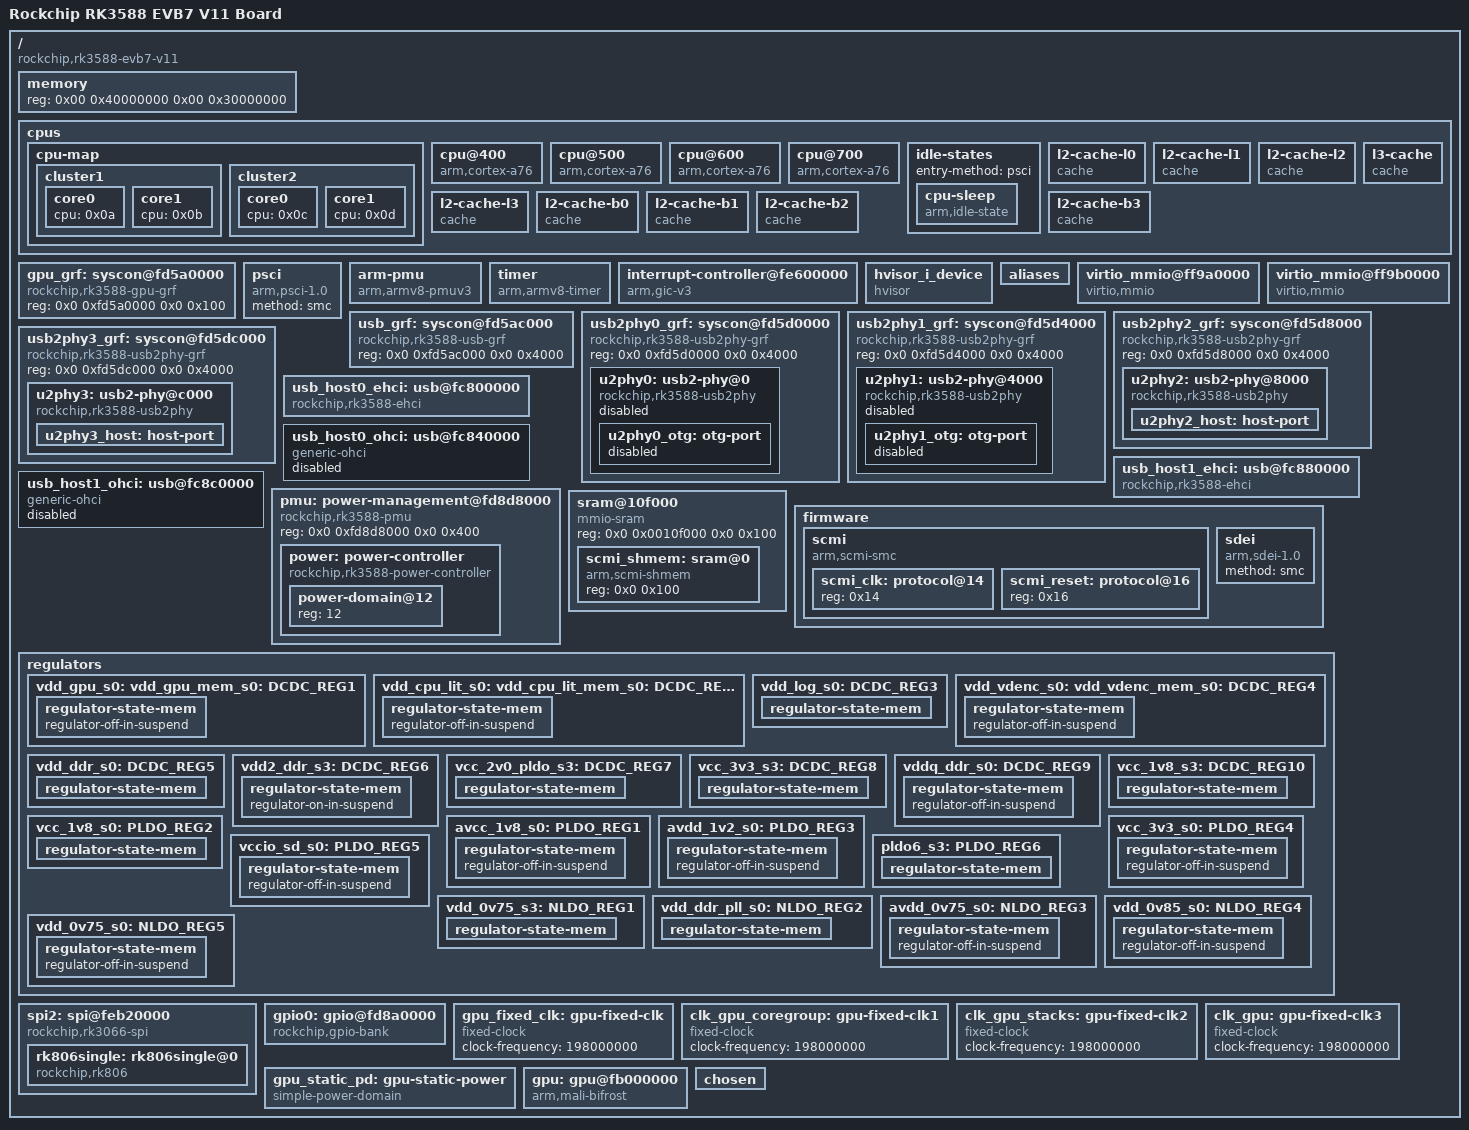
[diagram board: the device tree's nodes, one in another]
/dts-v1/;

/memreserve/	0x0000000008300000 0x0000000000047000;
/ {
	serial-number = "fe9d722c1f58159b";
	compatible = "rockchip,rk3588-evb7-v11\0rockchip,rk3588";
	interrupt-parent = <0x01>;
	#address-cells = <0x02>;
	#size-cells = <0x02>;
	model = "Rockchip RK3588 EVB7 V11 Board";

	memory {
		reg = <0x00 0x40000000 0x00 0x30000000>;
		device_type = "memory";
	};

	/*cpus 
		#address-cells = <0x01>;
		#size-cells = <0x00>;

		cpu-map {
			cluster0 {
				core2 {
					cpu = <0x08>;
				};

				core3 {
					cpu = <0x09>;
				};


			};
		};

		cpu@200 {
			device_type = "cpu";
			compatible = "arm,cortex-a55";
			reg = <0x200>;
			enable-method = "psci";
			capacity-dmips-mhz = <0x212>;
			clocks = <0x0e 0x00>;
			cpu-idle-states = <0x10>;
			i-cache-size = <0x8000>;
			i-cache-line-size = <0x40>;
			i-cache-sets = <0x80>;
			d-cache-size = <0x8000>;
			d-cache-line-size = <0x40>;
			d-cache-sets = <0x80>;
			next-level-cache = <0x14>;
			phandle = <0x08>;
		};


		cpu@300 {
			device_type = "cpu";
			compatible = "arm,cortex-a55";
			reg = <0x300>;
			enable-method = "psci";
			capacity-dmips-mhz = <0x212>;
			clocks = <0x0e 0x00>;
			cpu-idle-states = <0x10>;
			i-cache-size = <0x8000>;
			i-cache-line-size = <0x40>;
			i-cache-sets = <0x80>;
			d-cache-size = <0x8000>;
			d-cache-line-size = <0x40>;
			d-cache-sets = <0x80>;
			next-level-cache = <0x15>;
			phandle = <0x09>;
		};

*/
cpus {
		#address-cells = <0x01>;
		#size-cells = <0x00>;

		cpu-map {


			cluster1 {

				core0 {
					cpu = <0x0a>;
				};

				core1 {
					cpu = <0x0b>;
				};
			};


			cluster2 {

				core0 {
					cpu = <0x0c>;
				};

				core1 {
					cpu = <0x0d>;
				};
			};
		};

		cpu@400 {
			device_type = "cpu";
			compatible = "arm,cortex-a76";
			reg = <0x400>;
			enable-method = "psci";
			capacity-dmips-mhz = <0x400>;
			clocks = <0x0e 0x02>;
			operating-points-v2 = <0x0f>;
			cpu-idle-states = <0x10>;
			i-cache-size = <0x10000>;
			i-cache-line-size = <0x40>;
			i-cache-sets = <0x100>;
			d-cache-size = <0x10000>;
			d-cache-line-size = <0x40>;
			d-cache-sets = <0x100>;
			next-level-cache = <0x11>;
			#cooling-cells = <0x02>;
			dynamic-power-coefficient = <0x12c>;
			cpu-supply = <0x12>;
			mem-supply = <0x12>;
			phandle = <0x0a>;
		};

		cpu@500 {
			device_type = "cpu";
			compatible = "arm,cortex-a76";
			reg = <0x500>;
			enable-method = "psci";
			capacity-dmips-mhz = <0x400>;
			clocks = <0x0e 0x02>;
			operating-points-v2 = <0x0f>;
			cpu-idle-states = <0x10>;
			i-cache-size = <0x10000>;
			i-cache-line-size = <0x40>;
			i-cache-sets = <0x100>;
			d-cache-size = <0x10000>;
			d-cache-line-size = <0x40>;
			d-cache-sets = <0x100>;
			next-level-cache = <0x13>;
			phandle = <0x0b>;
		};


		cpu@600 {
			device_type = "cpu";
			compatible = "arm,cortex-a76";
			reg = <0x600>;
			enable-method = "psci";
			capacity-dmips-mhz = <0x400>;
			clocks = <0x0e 0x03>;
			operating-points-v2 = <0x14>;
			cpu-idle-states = <0x10>;
			i-cache-size = <0x10000>;
			i-cache-line-size = <0x40>;
			i-cache-sets = <0x100>;
			d-cache-size = <0x10000>;
			d-cache-line-size = <0x40>;
			d-cache-sets = <0x100>;
			next-level-cache = <0x15>;
			#cooling-cells = <0x02>;
			dynamic-power-coefficient = <0x12c>;
			cpu-supply = <0x16>;
			mem-supply = <0x16>;
			phandle = <0x0c>;
		};

		cpu@700 {
			device_type = "cpu";
			compatible = "arm,cortex-a76";
			reg = <0x700>;
			enable-method = "psci";
			capacity-dmips-mhz = <0x400>;
			clocks = <0x0e 0x03>;
			operating-points-v2 = <0x14>;
			cpu-idle-states = <0x10>;
			i-cache-size = <0x10000>;
			i-cache-line-size = <0x40>;
			i-cache-sets = <0x100>;
			d-cache-size = <0x10000>;
			d-cache-line-size = <0x40>;
			d-cache-sets = <0x100>;
			next-level-cache = <0x17>;
			phandle = <0x0d>;
		};

		idle-states {
			entry-method = "psci";
			cpu-sleep {
				compatible = "arm,idle-state";
				local-timer-stop;
				arm,psci-suspend-param = <0x10000>;
				entry-latency-us = <0x64>;
				exit-latency-us = <0x78>;
				min-residency-us = <0x3e8>;
				phandle = <0x10>;
			};
		};

		l2-cache-l0 {
			compatible = "cache";
			cache-size = <0x20000>;
			cache-line-size = <0x40>;
			cache-sets = <0x200>;
			next-level-cache = <0x1e>;
			phandle = <0x11>;
		};

		l2-cache-l1 {
			compatible = "cache";
			cache-size = <0x20000>;
			cache-line-size = <0x40>;
			cache-sets = <0x200>;
			next-level-cache = <0x1e>;
			phandle = <0x13>;
		};

		l2-cache-l2 {
			compatible = "cache";
			cache-size = <0x20000>;
			cache-line-size = <0x40>;
			cache-sets = <0x200>;
			next-level-cache = <0x1e>;
			phandle = <0x14>;
		};

		l2-cache-l3 {
			compatible = "cache";
			cache-size = <0x20000>;
			cache-line-size = <0x40>;
			cache-sets = <0x200>;
			next-level-cache = <0x1e>;
			phandle = <0x15>;
		};

		l2-cache-b0 {
			compatible = "cache";
			cache-size = <0x80000>;
			cache-line-size = <0x40>;
			cache-sets = <0x400>;
			next-level-cache = <0x1e>;
			phandle = <0x17>;
		};

		l2-cache-b1 {
			compatible = "cache";
			cache-size = <0x80000>;
			cache-line-size = <0x40>;
			cache-sets = <0x400>;
			next-level-cache = <0x1e>;
			phandle = <0x19>;
		};

		l2-cache-b2 {
			compatible = "cache";
			cache-size = <0x80000>;
			cache-line-size = <0x40>;
			cache-sets = <0x400>;
			next-level-cache = <0x1e>;
			phandle = <0x1b>;
		};

		l2-cache-b3 {
			compatible = "cache";
			cache-size = <0x80000>;
			cache-line-size = <0x40>;
			cache-sets = <0x400>;
			next-level-cache = <0x1e>;
			phandle = <0x1d>;
		};

		l3-cache {
			compatible = "cache";
			cache-size = <0x300000>;
			cache-line-size = <0x40>;
			cache-sets = <0x1000>;
			phandle = <0x1e>;
		};
	};

gpu_grf: syscon@fd5a0000 {
  compatible = "rockchip,rk3588-gpu-grf", "syscon";
  reg = <0x0 0xfd5a0000 0x0 0x100>;
 };

/*
php_grf: syscon@fd5b0000 {
  compatible = "rockchip,rk3588-php-grf", "syscon";
  reg = <0x0 0xfd5b0000 0x0 0x1000>;
 };

cru: clock-controller@fd7c0000 {
	     compatible = "rockchip,rk3588-cru";
	     rockchip,grf = <&php_grf>;
	     reg = <0x0 0xfd7c0000 0x0 0x5c000>;
#clock-cells = <1>;
#reset-cells = <1>;

	     assigned-clocks =
		     <&cru 9>, <&cru 5>,
		     <&cru 8>, <&cru 7>,
		     <&cru 216>,
		     <&cru 218>, <&cru 217>,
		     <&cru 270>, <&cru 271>,
		     <&cru 272>, <&cru 665>,
		     <&cru 666>,
		     <&cru 123>, <&cru 236>,
		     <&cru 276>, <&cru 520>,
		     <&cru 526>, <&cru 543>,
		     <&cru 119>;
	     assigned-clock-rates =
		     <1100000000>, <786432000>,
		     <850000000>, <1188000000>,
		     <702000000>,
		     <400000000>, <500000000>,
		     <750000000>, <100000000>,
		     <400000000>, <100000000>,
		     <200000000>,
		     <375000000>, <150000000>,
		     <200000000>, <12000000>,
		     <12000000>, <99000000>,
		     <20000000>;
     };


*/


	psci {
		compatible = "arm,psci-1.0";
		method = "smc";
	};

	arm-pmu {
		compatible = "arm,armv8-pmuv3";
		interrupts = <0x01 0x07 0x08>;
		interrupt-affinity = <0x06 0x07 0x08 0x09 0x0a 0x0b 0x0c 0x0d>;
		phandle = <0x220>;
	};

	timer {
		compatible = "arm,armv8-timer";
		interrupts = <0x01 0x0d 0xf04 0x01 0x0e 0xf04 0x01 0x0b 0xf04 0x01 0x0a 0xf04>;
	};

	interrupt-controller@fe600000 {
		compatible = "arm,gic-v3";
		#interrupt-cells = <0x03>;
		#address-cells = <0x02>;
		#size-cells = <0x02>;
		ranges;
		interrupt-controller;
		reg = <0x00 0xfe600000 0x00 0x10000 0x00 0xfe680000 0x00 0x100000>;
		interrupts = <0x01 0x09 0x04>;
		phandle = <0x01>;
	};
	hvisor_i_device {
                                compatible = "hvisor";
                                interrupt-parent = <0x01>;
                                interrupts = <0x00 0x22 0x01>;
                        };


	
    aliases {
	};

	// virtio blk
	virtio_mmio@ff9a0000 {
		dma-coherent;
		interrupt-parent = <0x01>;
		interrupts = <0x0 0x2e 0x1>;
		reg = <0x0 0xff9a0000 0x0 0x200>;
		compatible = "virtio,mmio";
	};

	// virtio serial
	virtio_mmio@ff9b0000 {
		dma-coherent;
		interrupt-parent = <0x01>;
		interrupts = <0x0 0x2c 0x1>;
		reg = <0x0 0xff9b0000 0x0 0x200>;
		compatible = "virtio,mmio";
	};


	// serial@feb50000 {
	// 	compatible = "rockchip,rk3588-uart\0snps,dw-apb-uart";
	// 	reg = <0x00 0xfeb50000 0x00 0x100>;
	// 	interrupts = <0x00 0x14d 0x04>;
	// 	//clocks = <0x02 0xbb 0x02 0xac>;
	// 	//clock-names = "baudclk\0apb_pclk";
	// 	reg-shift = <0x02>;
	// 	reg-io-width = <0x04>;
	// 	//pinctrl-names = "default";
	// 	//pinctrl-0 = <0x16d>;
	// 	status = "okay";
	// 	phandle = <0x2e2>;
	// };

/*
 php_grf: syscon@fd5b0000 {
  compatible = "rockchip,rk3588-php-grf", "syscon";
  reg = <0x0 0xfd5b0000 0x0 0x1000>;
 };


cru: clock-controller@fd7c0000 {
  compatible = "rockchip,rk3588-cru";
  rockchip,grf = <&php_grf>;
  reg = <0x0 0xfd7c0000 0x0 0x5c000>;
  #clock-cells = <1>;
  #reset-cells = <1>;

 };
*/


usb_grf: syscon@fd5ac000 {
  compatible = "rockchip,rk3588-usb-grf", "syscon";
  reg = <0x0 0xfd5ac000 0x0 0x4000>;
 };

usb2phy0_grf: syscon@fd5d0000 {
  compatible = "rockchip,rk3588-usb2phy-grf", "syscon",
        "simple-mfd";
  reg = <0x0 0xfd5d0000 0x0 0x4000>;
  #address-cells = <1>;
  #size-cells = <1>;

  u2phy0: usb2-phy@0 {
   compatible = "rockchip,rk3588-usb2phy";
   reg = <0x0 0x10>;
   interrupts = <0 393 4>;
  // resets = <&cru 786503>, <&cru 1160>;
 // reset-names = "phy", "apb";
   clock-output-names = "usb480m_phy0";
   #clock-cells = <0>;
   rockchip,usbctrl-grf = <&usb_grf>;
   status = "disable";

   u2phy0_otg: otg-port {
    #phy-cells = <0>;
    status = "disabled";
   };
  };
 };

 usb2phy1_grf: syscon@fd5d4000 {
  compatible = "rockchip,rk3588-usb2phy-grf", "syscon",
        "simple-mfd";
  reg = <0x0 0xfd5d4000 0x0 0x4000>;
  #address-cells = <1>;
  #size-cells = <1>;

  u2phy1: usb2-phy@4000 {
   compatible = "rockchip,rk3588-usb2phy";
   reg = <0x4000 0x10>;
   interrupts = <0 394 4>;
   //resets = <&cru 786504>, <&cru 1161>;
   //reset-names = "phy", "apb";
   //clocks = <&cru 693>;
   //clock-names = "phyclk";
   clock-output-names = "usb480m_phy1";
   #clock-cells = <0>;
   rockchip,usbctrl-grf = <&usb_grf>;
   status = "disable";

   u2phy1_otg: otg-port {
    #phy-cells = <0>;
    status = "disabled";
   };
  };
 };

usb2phy2_grf: syscon@fd5d8000 {
  compatible = "rockchip,rk3588-usb2phy-grf", "syscon",
        "simple-mfd";
  reg = <0x0 0xfd5d8000 0x0 0x4000>;
  #address-cells = <1>;
  #size-cells = <1>;

  u2phy2: usb2-phy@8000 {
   compatible = "rockchip,rk3588-usb2phy";
   reg = <0x8000 0x10>;
   interrupts = <0 391 4>;
   //resets = <&cru 786505>, <&cru 1162>;
   //reset-names = "phy", "apb";
   //clocks = <&cru 693>;
   //clock-names = "phyclk";
   clock-output-names = "usb480m_phy2";
   #clock-cells = <0>;
   status = "okay";

   u2phy2_host: host-port {
    #phy-cells = <0>;
    status = "okay";
   };
  };
 };


usb2phy3_grf: syscon@fd5dc000 {
  compatible = "rockchip,rk3588-usb2phy-grf", "syscon",
        "simple-mfd";
  reg = <0x0 0xfd5dc000 0x0 0x4000>;
  #address-cells = <1>;
  #size-cells = <1>;

  u2phy3: usb2-phy@c000 {
   compatible = "rockchip,rk3588-usb2phy";
   reg = <0xc000 0x10>;
   interrupts = <0 392 4>;
  // resets = <&cru 786506>, <&cru 1163>;
   //reset-names = "phy", "apb";
   //clocks = <&cru 693>;
   clock-names = "phyclk";
   clock-output-names = "usb480m_phy3";
   #clock-cells = <0>;
   status = "okay";

   u2phy3_host: host-port {
    #phy-cells = <0>;
    status = "okay";
   };
  };
 };
/*&u2phy0 {
 status = "okay";
};

*/
/*
&u2phy1 {
 status = "okay";
};

&u2phy2 {
 status = "okay";
};

&u2phy3 {
 status = "disable";
};



&u2phy2_host {
 //phy-supply = <&vcc5v0_host>;
 status = "okay";
};

&u2phy3_host {
 //phy-supply = <&vcc5v0_host>;
 status = "okay";
};
*/



usb_host0_ehci: usb@fc800000 {
  compatible = "rockchip,rk3588-ehci", "generic-ehci";
  reg = <0x0 0xfc800000 0x0 0x40000>;
  interrupts = <0 215 4>;
  //clocks = <&cru 413>, <&cru 414>, <&u2phy2>;
  //clock-names = "usbhost", "arbiter", "utmi";
  companion = <&usb_host0_ohci>;
  phys = <&u2phy2_host>;
  phy-names = "usb2-phy";
 // power-domains = <&power 31>;
  status = "okay";
 };

 usb_host0_ohci: usb@fc840000 {
  compatible = "generic-ohci";
  reg = <0x0 0xfc840000 0x0 0x40000>;
  interrupts = <0 216 4>;
  //clocks = <&cru 413>, <&cru 414>, <&u2phy2>;
  //clock-names = "usbhost", "arbiter", "utmi";
  phys = <&u2phy2_host>;
  phy-names = "usb2-phy";
  //power-domains = <&power 31>;
  status = "disable";
 };

/*
&usb_host0_ehci {
 status = "okay";
};

&usb_host0_ohci {
 status = "okay";
};
*/

usb_host1_ehci: usb@fc880000 {
  compatible = "rockchip,rk3588-ehci", "generic-ehci";
  reg = <0x0 0xfc880000 0x0 0x40000>;
  interrupts = <0 218 4>;
  //clocks = <&cru 415>, <&cru 416>, <&u2phy3>;
  //clock-names = "usbhost", "arbiter", "utmi";
  companion = <&usb_host1_ohci>;
  phys = <&u2phy3_host>;
  phy-names = "usb2-phy";
  //power-domains = <&power 31>;
  status = "okay";
 };

 usb_host1_ohci: usb@fc8c0000 {
  compatible = "generic-ohci";
  reg = <0x0 0xfc8c0000 0x0 0x40000>;
  interrupts = <0 219 4>;
  //clocks = <&cru 415>, <&cru 416>, <&u2phy3>;
  //clock-names = "usbhost", "arbiter", "utmi";
  phys = <&u2phy3_host>;
  phy-names = "usb2-phy";
  //power-domains = <&power 31>;
  status = "disable";
 };

/*
&usb_host1_ehci {
 status = "okay";
};

&usb_host1_ohci {
 status = "okay";
};
*/
/*
usbdrd3_1: usbdrd3_1 {
  compatible = "rockchip,rk3588-dwc3", "rockchip,rk3399-dwc3";
  //clocks = <&cru 422>, <&cru 421>,
   // <&cru 420>;
  //clock-names = "ref", "suspend", "bus";
  #address-cells = <2>;
  #size-cells = <2>;
  ranges;
  status = "okay";

  usbdrd_dwc3_1: usb@fc400000 {
   compatible = "snps,dwc3";
   reg = <0x0 0xfc400000 0x0 0x400000>;
   interrupts = <0 221 4>;
   //power-domains = <&power 31>;
   //resets = <&cru 679>;
   //reset-names = "usb3-otg";
   dr_mode = "host";
   phys = <&usbdp_phy1_u3>;
   phy-names = "usb3-phy";
   phy_type = "utmi_wide";
   snps,dis_enblslpm_quirk;
   snps,dis-u1-entry-quirk;
   snps,dis-u2-entry-quirk;
   snps,dis-u2-freeclk-exists-quirk;
   snps,dis-del-phy-power-chg-quirk;
   snps,dis-tx-ipgap-linecheck-quirk;
   snps,parkmode-disable-ss-quirk;
   status = "okay";
  };
 };
*/

 pmu: power-management@fd8d8000 {
  compatible = "rockchip,rk3588-pmu", "syscon", "simple-mfd";
  reg = <0x0 0xfd8d8000 0x0 0x400>;

  power: power-controller {
   compatible = "rockchip,rk3588-power-controller";
   #power-domain-cells = <1>;
   #address-cells = <1>;
   #size-cells = <0>;
   status = "okay";
	 power-domain@12 {

    		reg = <12>;
};

     };
 };


sram@10f000 {
  compatible = "mmio-sram";
  reg = <0x0 0x0010f000 0x0 0x100>;
  #address-cells = <1>;
  #size-cells = <1>;
  ranges = <0 0x0 0x0010f000 0x100>;

  scmi_shmem: sram@0 {
   compatible = "arm,scmi-shmem";
   reg = <0x0 0x100>;
  };
 };

firmware {
  scmi: scmi {
   compatible = "arm,scmi-smc";
   shmem = <&scmi_shmem>;
   arm,smc-id = <0x82000010>;
   #address-cells = <1>;
   #size-cells = <0>;

   scmi_clk: protocol@14 {
    reg = <0x14>;
    #clock-cells = <1>;
   };

   scmi_reset: protocol@16 {
    reg = <0x16>;
    #reset-cells = <1>;
   };
  };

  sdei: sdei {
   compatible = "arm,sdei-1.0";
   method = "smc";
  };
 };








regulators {
   vdd_gpu_s0: vdd_gpu_mem_s0: DCDC_REG1 {
    regulator-boot-on;
    regulator-min-microvolt = <550000>;
    regulator-max-microvolt = <950000>;
    regulator-ramp-delay = <12500>;
    regulator-name = "vdd_gpu_s0";
    regulator-enable-ramp-delay = <400>;
    regulator-state-mem {
     regulator-off-in-suspend;
    };
   };

   vdd_cpu_lit_s0: vdd_cpu_lit_mem_s0: DCDC_REG2 {
    regulator-always-on;
    regulator-boot-on;
    regulator-min-microvolt = <550000>;
    regulator-max-microvolt = <950000>;
    regulator-ramp-delay = <12500>;
    regulator-name = "vdd_cpu_lit_s0";
    regulator-state-mem {
     regulator-off-in-suspend;
    };
   };

   vdd_log_s0: DCDC_REG3 {
    regulator-always-on;
    regulator-boot-on;
    regulator-min-microvolt = <675000>;
    regulator-max-microvolt = <750000>;
    regulator-ramp-delay = <12500>;
    regulator-name = "vdd_log_s0";
    regulator-state-mem {
     regulator-off-in-suspend;
     regulator-suspend-microvolt = <750000>;
    };
   };

   vdd_vdenc_s0: vdd_vdenc_mem_s0: DCDC_REG4 {
    regulator-always-on;
    regulator-boot-on;
    regulator-min-microvolt = <550000>;
    regulator-max-microvolt = <950000>;
    regulator-init-microvolt = <750000>;
    regulator-ramp-delay = <12500>;
    regulator-name = "vdd_vdenc_s0";
    regulator-state-mem {
     regulator-off-in-suspend;
    };
   };

   vdd_ddr_s0: DCDC_REG5 {
    regulator-always-on;
    regulator-boot-on;
    regulator-min-microvolt = <675000>;
    regulator-max-microvolt = <900000>;
    regulator-ramp-delay = <12500>;
    regulator-name = "vdd_ddr_s0";
    regulator-state-mem {
     regulator-off-in-suspend;
     regulator-suspend-microvolt = <850000>;
    };
   };

   vdd2_ddr_s3: DCDC_REG6 {
    regulator-always-on;
    regulator-boot-on;
    regulator-name = "vdd2_ddr_s3";
    regulator-state-mem {
     regulator-on-in-suspend;
    };
   };

   vcc_2v0_pldo_s3: DCDC_REG7 {
    regulator-always-on;
    regulator-boot-on;
    regulator-min-microvolt = <2000000>;
    regulator-max-microvolt = <2000000>;
    regulator-name = "vdd_2v0_pldo_s3";
    regulator-state-mem {
     regulator-on-in-suspend;
     regulator-suspend-microvolt = <2000000>;
    };
   };

   vcc_3v3_s3: DCDC_REG8 {
    regulator-always-on;
    regulator-boot-on;
    regulator-min-microvolt = <3300000>;
    regulator-max-microvolt = <3300000>;
    regulator-name = "vcc_3v3_s3";
    regulator-state-mem {
     regulator-on-in-suspend;
     regulator-suspend-microvolt = <3300000>;
    };
   };

   vddq_ddr_s0: DCDC_REG9 {
    regulator-always-on;
    regulator-boot-on;
    regulator-name = "vddq_ddr_s0";
    regulator-state-mem {
     regulator-off-in-suspend;
    };
   };

   vcc_1v8_s3: DCDC_REG10 {
    regulator-always-on;
    regulator-boot-on;
    regulator-min-microvolt = <1800000>;
    regulator-max-microvolt = <1800000>;
    regulator-name = "vcc_1v8_s3";
    regulator-state-mem {
     regulator-on-in-suspend;
     regulator-suspend-microvolt = <1800000>;
    };
   };

   avcc_1v8_s0: PLDO_REG1 {
    regulator-always-on;
    regulator-boot-on;
    regulator-min-microvolt = <1800000>;
    regulator-max-microvolt = <1800000>;
    regulator-name = "avcc_1v8_s0";
    regulator-state-mem {
     regulator-off-in-suspend;
    };
   };

   vcc_1v8_s0: PLDO_REG2 {
    regulator-always-on;
    regulator-boot-on;
    regulator-min-microvolt = <1800000>;
    regulator-max-microvolt = <1800000>;
    regulator-name = "vcc_1v8_s0";
    regulator-state-mem {
     regulator-off-in-suspend;
     regulator-suspend-microvolt = <1800000>;
    };
   };

   avdd_1v2_s0: PLDO_REG3 {
    regulator-always-on;
    regulator-boot-on;
    regulator-min-microvolt = <1200000>;
    regulator-max-microvolt = <1200000>;
    regulator-name = "avdd_1v2_s0";
    regulator-state-mem {
     regulator-off-in-suspend;
    };
   };

   vcc_3v3_s0: PLDO_REG4 {
    regulator-always-on;
    regulator-boot-on;
    regulator-min-microvolt = <3300000>;
    regulator-max-microvolt = <3300000>;
    regulator-name = "vcc_3v3_s0";
    regulator-state-mem {
     regulator-off-in-suspend;
    };
   };

   vccio_sd_s0: PLDO_REG5 {
    regulator-always-on;
    regulator-boot-on;
    regulator-min-microvolt = <1800000>;
    regulator-max-microvolt = <3300000>;
    regulator-name = "vccio_sd_s0";
    regulator-state-mem {
     regulator-off-in-suspend;
    };
   };

   pldo6_s3: PLDO_REG6 {
    regulator-always-on;
    regulator-boot-on;
    regulator-min-microvolt = <1800000>;
    regulator-max-microvolt = <1800000>;
    regulator-name = "pldo6_s3";
    regulator-state-mem {
     regulator-on-in-suspend;
     regulator-suspend-microvolt = <1800000>;
    };
   };

   vdd_0v75_s3: NLDO_REG1 {
    regulator-always-on;
    regulator-boot-on;
    regulator-min-microvolt = <750000>;
    regulator-max-microvolt = <750000>;
    regulator-name = "vdd_0v75_s3";
    regulator-state-mem {
     regulator-on-in-suspend;
     regulator-suspend-microvolt = <750000>;
    };
   };

   vdd_ddr_pll_s0: NLDO_REG2 {
    regulator-always-on;
    regulator-boot-on;
    regulator-min-microvolt = <850000>;
    regulator-max-microvolt = <850000>;
    regulator-name = "vdd_ddr_pll_s0";
    regulator-state-mem {
     regulator-off-in-suspend;
     regulator-suspend-microvolt = <850000>;
    };
   };

   avdd_0v75_s0: NLDO_REG3 {
    regulator-always-on;
    regulator-boot-on;
    regulator-min-microvolt = <837500>;
    regulator-max-microvolt = <837500>;
    regulator-name = "avdd_0v75_s0";
    regulator-state-mem {
     regulator-off-in-suspend;
    };
   };

   vdd_0v85_s0: NLDO_REG4 {
    regulator-always-on;
    regulator-boot-on;
    regulator-min-microvolt = <850000>;
    regulator-max-microvolt = <850000>;
    regulator-name = "vdd_0v85_s0";
    regulator-state-mem {
     regulator-off-in-suspend;
    };
   };

   vdd_0v75_s0: NLDO_REG5 {
    regulator-always-on;
    regulator-boot-on;
    regulator-min-microvolt = <750000>;
    regulator-max-microvolt = <750000>;
    regulator-name = "vdd_0v75_s0";
    regulator-state-mem {
     regulator-off-in-suspend;
    };
   };
  };
spi2: spi@feb20000{
  compatible = "rockchip,rk3066-spi";
  reg = <0x0 0xfeb20000 0x0 0x1000>;
  interrupts = <0 328 4>;
  #address-cells = <1>;
  #size-cells = <0>;
  num-cs = <2>;
 assigned-clock-rates = <200000000>;
 status = "disable";
 };
gpio0: gpio@fd8a0000 {
   compatible = "rockchip,gpio-bank";
   reg = <0x0 0xfd8a0000 0x0 0x100>;
   interrupts = <0 277 4>;

   gpio-controller;
   #gpio-cells = <2>;
   interrupt-controller;
   #interrupt-cells = <2>;
  };

/*
	gpu: gpu@fb000000 {
	     compatible = "arm,mali-bifrost";
	     reg = <0x0 0xfb000000 0x0 0x200000>;
	     interrupts = <0 94 4>,
			<0 93 4>,
			<0 92 4>;
	     interrupt-names = "GPU", "MMU", "JOB";

  	     assigned-clocks = <&scmi_clk 5>;
  	     assigned-clock-rates = <200000000>;

	      power-domains = <&power 12>;
	      #cooling-cells = <2>;
	     dynamic-power-coefficient = <2982>;

	     upthreshold = <30>;
	     downdifferential = <10>;
	     mali-supply = <&vdd_gpu_s0>;
	     mem-supply = <&vdd_gpu_mem_s0>;
	     status = "okay";
     };
*/


/*
 gpu: gpu@fb000000 {
  compatible = "arm,mali-bifrost";
  reg = <0x0 0xfb000000 0x0 0x200000>;
  interrupts = <0 94 4>,
        <0 93 4>,
        <0 92 4>;
  interrupt-names = "GPU", "MMU", "JOB";

  //power-domains = <&power 12>;
  assigned-clocks = <&scmi_clk 5>;
  assigned-clock-rates = <200000000>;
  #cooling-cells = <2>;
  //dynamic-power-coefficient = <2982>;

  //upthreshold = <30>;
  //downdifferential = <10>;
  //mali-supply = <&vdd_gpu_s0>;
  //mem-supply = <&vdd_gpu_mem_s0>;
  status = "okay";
 };*/





gpu_fixed_clk: gpu-fixed-clk {
    compatible = "fixed-clock";
    #clock-cells = <0>;
    clock-frequency = <198000000>; /* 这里填你的固定频率，单位Hz */
};

clk_gpu_coregroup: gpu-fixed-clk1 {
    compatible = "fixed-clock";
    #clock-cells = <0>;
    clock-frequency = <198000000>; /* 这里填你的固定频率，单位Hz */
};
clk_gpu_stacks: gpu-fixed-clk2 {
    compatible = "fixed-clock";
    #clock-cells = <0>;
    clock-frequency = <198000000>; /* 这里填你的固定频率，单位Hz */
};
clk_gpu: gpu-fixed-clk3 {
    compatible = "fixed-clock";
    #clock-cells = <0>;
    clock-frequency = <198000000>; /* 这里填你的固定频率，单位Hz */
};



gpu_static_pd: gpu-static-power {
    compatible = "simple-power-domain";
    #power-domain-cells = <0>;
    status = "okay"; /* always-on */
};


gpu: gpu@fb000000 {
  compatible = "arm,mali-bifrost";
  reg = <0x0 0xfb000000 0x0 0x200000>;
  interrupts = <0 94 4>,
        <0 93 4>,
        <0 92 4>;
  interrupt-names = "GPU", "MMU", "JOB";

  clocks = <&gpu_fixed_clk>,<&clk_gpu_coregroup>,<&clk_gpu_stacks>,<&clk_gpu>;
  clock-names = "clk_mali","clk_gpu_coregroup","clk_gpu_stacks", "clk_gpu";

  //power-domains = <&gpu_static_pd>;
   power-domains = <&power 12>;
  assigned-clocks = <&scmi_clk 5>;
  assigned-clock-rates = <200000000>;
  #cooling-cells = <2>;
  //dynamic-power-coefficient = <2982>;

  //upthreshold = <30>;
  //downdifferential = <10>;
  //mali-supply = <&vdd_gpu_s0>;
  //mem-supply = <&vdd_gpu_mem_s0>;
  status = "okay";
 };






		
    chosen {
		bootargs = "earlycon=virtio,mmio,0xff9b0000 console=hvc0 root=/dev/vda rootwait rw loglevel=9 clk_ignore_unused";
//		stdout-path = "/virtio_mmio@0xff9b0000";
	};
};
&spi2 {
 status = "okay";
 assigned-clock-rates = <200000000>;
 num-cs = <1>;

 rk806single: rk806single@0 {
  compatible = "rockchip,rk806";
  spi-max-frequency = <1000000>;
  reg = <0x0>;

  interrupt-parent = <&gpio0>;
  interrupts = <7 8>;
  low_voltage_threshold = <3000>;
  shutdown_voltage_threshold = <2700>;
  shutdown_temperture_threshold = <160>;
  hotdie_temperture_threshold = <115>;
  pmic-reset-func = <1>;
};
};
